# ATtiny816 device description
Architecture: AVR8X; Family: AVR TINY
Registers are 8-bit, read-write, no defined reset value unless marked. A register's access mark holds for its fields unless they carry their own. Offsets are from the block's base; [hi:lo] are bit positions; {n}, {i} and the like mark numbered series; 'fields as' and 'values as' point back to an identical list; <NAME> marks a mode.

## SIGROW — Signature row
Instances: SIGROW 0x1100
{0x0+i} DEVICEID{i} ro (i=0..2) — Device ID Byte {i}
{0x3+i} SERNUM{i} ro (i=0..9) — Serial Number Byte {i}
0x20 TEMPSENSE0 ro — Temperature Sensor Calibration Byte 0
0x21 TEMPSENSE1 ro — Temperature Sensor Calibration Byte 1

## SLPCTRL — Sleep Controller
Instances: SLPCTRL 0x0050
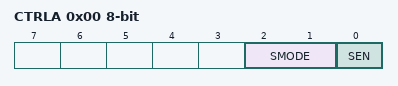
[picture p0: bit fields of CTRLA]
0x00 CTRLA — Control
  [2:1] SMODE — Sleep mode
    0=IDLE (Idle mode); 1=STDBY (Standby Mode); 2=PDOWN (Power-down Mode)
  [0] SEN — Sleep enable

## SPI — Serial Peripheral Interface
Instances: SPI0 0x0820
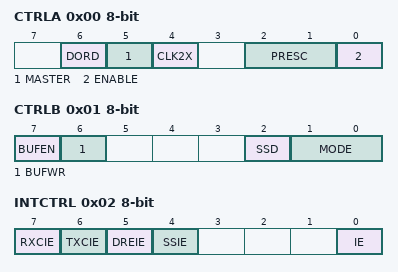
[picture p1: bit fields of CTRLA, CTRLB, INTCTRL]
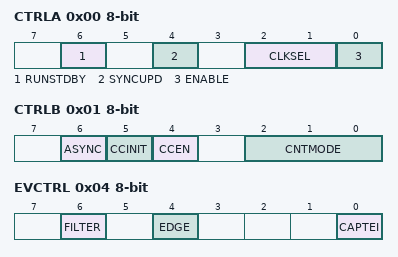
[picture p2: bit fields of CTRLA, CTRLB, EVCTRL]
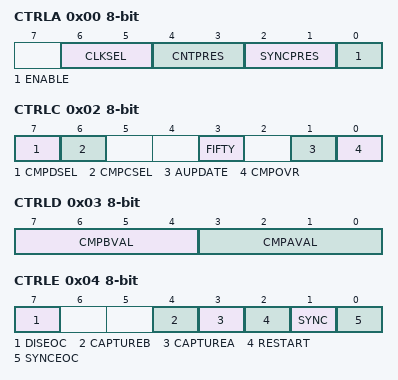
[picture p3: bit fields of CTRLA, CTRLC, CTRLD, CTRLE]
0x00 CTRLA — Control A
  [6] DORD — Data Order Setting
  [5] MASTER — Master Operation Enable
  [4] CLK2X — Enable Double Speed
  [2:1] PRESC — Prescaler
    0=DIV4 (System Clock / 4); 1=DIV16 (System Clock / 16); 2=DIV64 (System Clock / 64); 3=DIV128 (System Clock / 128)
  [0] ENABLE — Enable Module
0x01 CTRLB — Control B
  [7] BUFEN — Buffer Mode Enable
  [6] BUFWR — Buffer Write Mode
  [2] SSD — Slave Select Disable
  [1:0] MODE — SPI Mode
    {v}=SPI Mode {v} (v=0..3)
0x02 INTCTRL — Interrupt Control
  [7] RXCIE — Receive Complete Interrupt Enable
  [6] TXCIE — Transfer Complete Interrupt Enable
  [5] DREIE — Data Register Empty Interrupt Enable
  [4] SSIE — Slave Select Trigger Interrupt Enable
  [0] IE — Interrupt Enable
0x03 INTFLAGS — Interrupt Flags
  [7] RXCIF <Buffer_mode> — Receive Complete Interrupt Flag
  [6] TXCIF <Buffer_mode> — Transfer Complete Interrupt Flag
  [5] DREIF <Buffer_mode> — Data Register Empty Interrupt Flag
  [4] SSIF <Buffer_mode> — Slave Select Trigger Interrupt Flag
  [0] BUFOVF <Buffer_mode> — Buffer Overflow
  [7] IF <Default_mode> — Interrupt Flag
  [6] WRCOL <Default_mode> — Write Collision
0x04 DATA

## SYSCFG — System Configuration Registers
Instances: SYSCFG 0x0F00
0x01 REVID — Revision ID
0x02 EXTBRK — External Break
  [0] ENEXTBRK — External break enable

## TCB — 16-bit Timer Type B
Instances: TCB0 0x0A40
0x00 CTRLA — Control A
  [6] RUNSTDBY — Run Standby
  [4] SYNCUPD — Synchronize Update
  [2:1] CLKSEL — Clock Select
    0=CLKDIV1 (CLK_PER (No Prescaling)); 1=CLKDIV2 (CLK_PER/2 (From Prescaler)); 2=CLKTCA (Use Clock from TCA)
  [0] ENABLE
0x01 CTRLB — Control Register B
  [6] ASYNC — Asynchronous Enable
  [5] CCINIT — Pin Initial State
  [4] CCEN — Pin Output Enable
  [2:0] CNTMODE — Timer Mode
    0=INT (Periodic Interrupt); 1=TIMEOUT (Periodic Timeout); 2=CAPT (Input Capture Event); 3=FRQ (Input Capture Frequency measurement); 4=PW (Input Capture Pulse-Width measurement); 5=FRQPW (Input Capture Frequency and Pulse-Width measurement); 6=SINGLE (Single Shot); 7=PWM8 (8-bit PWM)
0x04 EVCTRL — Event Control
  [6] FILTER — Input Capture Noise Cancellation Filter
  [4] EDGE — Event Edge
  [0] CAPTEI — Event Input Enable
0x05 INTCTRL — Interrupt Control
  [0] CAPT — Capture or Timeout
0x06 INTFLAGS — Interrupt Flags
  [0] CAPT — Capture or Timeout
0x07 STATUS
  [0] RUN
0x08 DBGCTRL — Debug Control
  [0] DBGRUN — Debug Run
0x09 TEMP — Temporary Value
0x0A CNT 16-bit — Count
0x0C CCMP 16-bit — Compare or Capture

## TCD — Timer Counter D
Instances: TCD0 0x0A80
0x00 CTRLA — Control A
  [6:5] CLKSEL — clock select
    0=20MHZ (20 MHz oscillator); 2=EXTCLK (External clock); 3=SYSCLK (System clock)
  [4:3] CNTPRES — counter prescaler
    0=DIV1 (Sync clock divided by 1); 1=DIV4 (Sync clock divided by 4); 2=DIV32 (Sync clock divided by 32)
  [2:1] SYNCPRES — Syncronization prescaler
    0=DIV1 (Selevted clock source divided by 1); 1=DIV2 (Selevted clock source divided by 2); 2=DIV4 (Selevted clock source divided by 4); 3=DIV8 (Selevted clock source divided by 8)
  [0] ENABLE
0x01 CTRLB — Control B
  [1:0] WGMODE — Waveform generation mode
    0=ONERAMP (One ramp mode); 1=TWORAMP (Two ramp mode); 2=FOURRAMP (Four ramp mode); 3=DS (Dual slope mode)
0x02 CTRLC — Control C
  [7] CMPDSEL — Compare D output select
    0=PWMA (PWM A output); 1=PWMB (PWM B output)
  [6] CMPCSEL — Compare C output select
    0=PWMA (PWM A output); 1=PWMB (PWM B output)
  [3] FIFTY — Fifty percent waveform
  [1] AUPDATE — Auto update
  [0] CMPOVR — Compare output value override
0x03 CTRLD — Control D
  [7:4] CMPBVAL — Compare B value
  [3:0] CMPAVAL — Compare A value
0x04 CTRLE — Control E
  [7] DISEOC — Disable at end of cycle
  [4] CAPTUREB — Capture b strobe
  [3] CAPTUREA — Capture a strobe
  [2] RESTART — Restart strobe
  [1] SYNC — synchronize strobe
  [0] SYNCEOC — synchronize end of cycle strobe
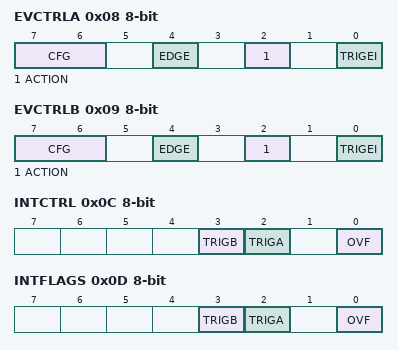
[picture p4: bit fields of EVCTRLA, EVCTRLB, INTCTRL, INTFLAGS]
0x08 EVCTRLA
  [7:6] CFG — event config
    1=FILTER (Filter functionality on); 2=ASYNC (Async functionality on)
  [4] EDGE — edge select
    0=FALL_LOW (The falling edge or low level of event generates retrigger or fault action); 1=RISE_HIGH (The rising edge or high level of event generates retrigger or fault action)
  [2] ACTION — event action
    0=FAULT (Event trigger a fault); 1=CAPTURE (Event trigger a fault and capture)
  [0] TRIGEI — Trigger event enable
0x09 EVCTRLB
  fields as EVCTRLA
0x0C INTCTRL — Interrupt Control
  [3] TRIGB — Trigger B interrupt enable
  [2] TRIGA — Trigger A interrupt enable
  [0] OVF — Overflow interrupt enable
0x0D INTFLAGS — Interrupt Flags
  fields as INTCTRL
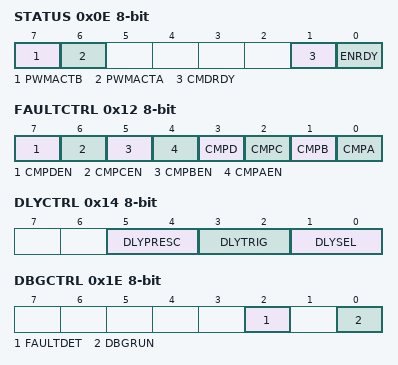
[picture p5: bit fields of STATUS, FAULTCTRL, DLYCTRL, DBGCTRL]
0x0E STATUS
  [7] PWMACTB — PWM activity on B
  [6] PWMACTA — PWM activity on A
  [1] CMDRDY — Command ready
  [0] ENRDY — Enable ready
0x10 INPUTCTRLA — Input Control A
  [3:0] INPUTMODE
0x11 INPUTCTRLB — Input Control B
  [3:0] INPUTMODE
0x12 FAULTCTRL — Fault Control
  [7] CMPDEN — Compare D enable
  [6] CMPCEN — Compare C enable
  [5] CMPBEN — Compare B enable
  [4] CMPAEN — Compare A enable
  [3] CMPD — Compare D vaule
  [2] CMPC — Compare C value
  [1] CMPB — Compare B value
  [0] CMPA — Compare A value
0x14 DLYCTRL — Delay Control
  [5:4] DLYPRESC — Delay prescaler
    0=DIV1 (No prescaling); 1=DIV2 (Prescale with 2); 2=DIV4 (Prescale with 4); 3=DIV8 (Prescale with 8)
  [3:2] DLYTRIG — Delay trigger
    0=CMPASET (Compare A set); 1=CMPACLR (Compare A clear); 2=CMPBSET (Compare B set); 3=CMPBCLR (Compare B clear)
  [1:0] DLYSEL — Delay select
    0=OFF (No delay); 1=INBLANK (Input blanking enabled); 2=EVENT (Event delay enabled)
0x15 DLYVAL — Delay value
0x18 DITCTRL — Dither Control A
  [1:0] DITHERSEL — dither select
    0=ONTIMEB (On-time ramp B); 1=ONTIMEAB (On-time ramp A and B); 2=DEADTIMEB (Dead-time rampB); 3=DEADTIMEAB (Dead-time ramp A and B)
0x19 DITVAL — Dither value
  [3:0] DITHER
0x1E DBGCTRL — Debug Control
  [2] FAULTDET — Fault detection
  [0] DBGRUN — Debug run
0x22 SCAPTUREA 16-bit — Capture A
0x24 SCAPTUREB 16-bit — Capture B
0x28 CMPASET 16-bit — Compare A Set
0x2A CMPACLR 16-bit — Compare A Clear
0x2C CMPBSET 16-bit — Compare B Set
0x2E CMPBCLR 16-bit — Compare B Clear
